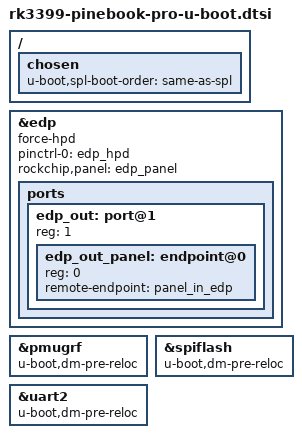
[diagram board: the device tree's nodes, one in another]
// SPDX-License-Identifier: GPL-2.0+
/*
 * Copyright (C) 2019 Peter Robinson <pbrobinson at gmail.com>
 */

#include "rk3399-u-boot.dtsi"
#include "rk3399-sdram-lpddr4-100.dtsi"

/ {
	chosen {
		u-boot,spl-boot-order = "same-as-spl", &sdhci, &sdmmc;
	};
};

&edp {
	force-hpd;
	pinctrl-names = "default";
	pinctrl-0 = <&edp_hpd>;
	status = "okay";

	rockchip,panel = <&edp_panel>;

	ports {
		edp_out: port@1 {
			reg = <1>;
			#address-cells = <1>;
			#size-cells = <0>;

			edp_out_panel: endpoint@0 {
				reg = <0>;
				remote-endpoint = <&panel_in_edp>;
			};
		};
	};
};

&pmugrf {
	u-boot,dm-pre-reloc;
};

&spiflash {
        u-boot,dm-pre-reloc;
};

&uart2 {
        u-boot,dm-pre-reloc;
};
